AUTOSAR XML (schema 4-2-2)
standard types defined: boolean, float32, float64, sint16, sint32, sint64, sint8, uint16, uint32, uint64, uint8, void
package /BSW/ImplementationDataTypes
  6 x impl type:
    EcuM_BootTargetType: compu {0=ECUM_BOOT_TARGET_APP, 1=ECUM_BOOT_TARGET_OEM_BOOTLOADER, 2=ECUM_BOOT_TARGET_SYS_BOOTLOADER}, implementation-data-type=uint8
    EcuM_ShutdownCauseType: compu {0=ECUM_CAUSE_UNKNOWN, 1=ECUM_CAUSE_ECU_STATE, 2=ECUM_CAUSE_WDGM, 3=ECUM_CAUSE_DCM}, implementation-data-type=uint8
    EcuM_ShutdownModeType: category=VALUE, base-type=uint16
    EcuM_ShutdownTargetType: compu {0x0=ECUM_SHUTDOWN_TARGET_SLEEP, 0x1=ECUM_SHUTDOWN_TARGET_RESET, 0x2=ECUM_SHUTDOWN_TARGET_OFF}, implementation-data-type=uint8
    EcuM_TimeType: implementation-data-type=uint32
    EcuM_UserType: implementation-data-type=uint8
package /BSW/ModeDeclarationGroups
  mode declaration group EcuM_Mode: category=ALPHABETIC_ORDER, initial-mode=STARTUP, on-transition-value=5
    5 x mode:
      POST_RUN: value=0
      RUN: value=1
      SHUTDOWN: value=2
      SLEEP: value=3
      STARTUP: value=4
package /BSW/PortInterfaces
  4 x client server interface, all with service-kind=ECU-MANAGER:
    EcuM_BootTarget
      operation GetBootTarget: possible-error=EcuM_BootTarget/E_OK
        arg target: type=EcuM_BootTargetType, direction=OUT
      operation SelectBootTarget: possible-error=[EcuM_BootTarget/E_NOT_OK, EcuM_BootTarget/E_OK]
        arg target: type=EcuM_BootTargetType, direction=IN
      error E_NOT_OK: error-code=1
      error E_OK: error-code=0
    EcuM_ShutdownTarget
      5 x operation, all with possible-error=[EcuM_ShutdownTarget/E_NOT_OK, EcuM_ShutdownTarget/E_OK]:
        GetLastShutdownTarget
          arg shutdownTarget: type=EcuM_ShutdownTargetType, direction=OUT
          arg shutdownMode: type=EcuM_ShutdownModeType, direction=OUT
        GetShutdownCause
          arg shutdownCause: type=EcuM_ShutdownCauseType, direction=OUT
        GetShutdownTarget
          arg shutdownTarget: type=EcuM_ShutdownTargetType, direction=OUT
          arg shutdownMode: type=EcuM_ShutdownModeType, direction=OUT
        SelectShutdownCause
          arg shutdownCause: type=EcuM_ShutdownCauseType, direction=IN
        SelectShutdownTarget
          arg shutdownTarget: type=EcuM_ShutdownTargetType, direction=IN
          arg shutdownMode: type=EcuM_ShutdownModeType, direction=IN
      error E_NOT_OK: error-code=1
      error E_OK: error-code=0
    EcuM_StateRequest
      4 x operation, all with possible-error=[EcuM_StateRequest/E_NOT_OK, EcuM_StateRequest/E_OK]:
        ReleasePOSTRUN
        ReleaseRUN
        RequestPOSTRUN
        RequestRUN
      error E_NOT_OK: error-code=1
      error E_OK: error-code=0
    EcuM_Time
      operation GetCurrentTime: possible-error=[EcuM_Time/E_NOT_OK, EcuM_Time/E_OK]
        arg time: type=EcuM_TimeType, direction=OUT
      operation GetWakeupTime: possible-error=[EcuM_Time/E_NOT_OK, EcuM_Time/E_OK]
        arg time: type=EcuM_TimeType, direction=OUT
      error E_NOT_OK: error-code=1
      error E_OK: error-code=0
  mode switch interface EcuM_CurrentMode: service-kind=ECU-MANAGER
    mode group currentMode: type=EcuM_Mode
package /BSW/SWCs
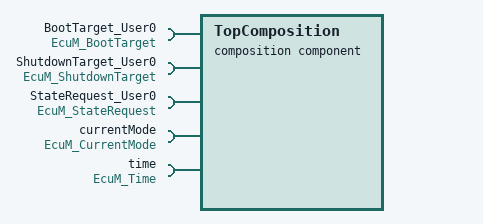
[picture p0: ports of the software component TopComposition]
  composition sw component type TopComposition
    5 x require port:
      BootTarget_User0: required-interface=EcuM_BootTarget
      ShutdownTarget_User0: required-interface=EcuM_ShutdownTarget
      StateRequest_User0: required-interface=EcuM_StateRequest
      currentMode: required-interface=EcuM_CurrentMode
      time: required-interface=EcuM_Time
